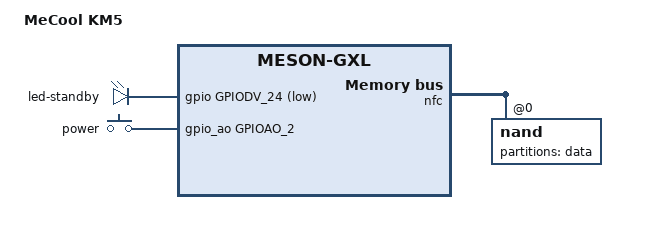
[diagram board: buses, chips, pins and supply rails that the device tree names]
// SPDX-License-Identifier: (GPL-2.0+ OR MIT)
/*
 * Copyright (c) 2018 He Yangxuan
 */

/dts-v1/;

#include "meson-gxl-s905x-p212.dts"
#include <dt-bindings/input/input.h>
#include <dt-bindings/leds/common.h>

/ {
	compatible = "videostrong,gxl-km5", "amlogic,s905x", "amlogic,meson-gxl";
	model = "MeCool KM5";

	leds {
		compatible = "gpio-leds";

		led-standby {
			function = LED_FUNCTION_STANDBY;
			gpios = <&gpio GPIODV_24 GPIO_ACTIVE_LOW>;
			default-state = "off";
		};
	};

	gpio-keys-polled {
		compatible = "gpio-keys-polled";
		poll-interval = <100>;

		power-button {
			label = "power";
			linux,code = <KEY_POWER>;
			gpios = <&gpio_ao GPIOAO_2 GPIO_ACTIVE_HIGH>;
		};
	};
};

&emmc_pwrseq {
	status = "disabled";
};

&nfc {
	status = "okay";

	nand@0 {
		reg = <0>;
		nand-on-flash-bbt;
		nand-ecc-strength = <50>;
		nand-ecc-step-size = <1024>;

		partitions {
			compatible = "fixed-partitions";
			#address-cells = <2>;
			#size-cells = <2>;

			partition@0 {
				label = "data";
				reg = <0x0 0x0 0x2 0x0>;
				compatible = "linux,ubi";
				slc-mode;
			};
		};
	};
};

&sd_emmc_c {
	status = "disabled";
};
